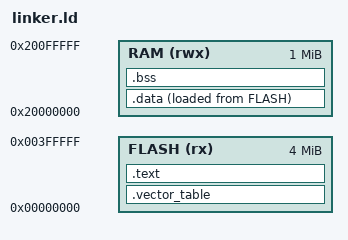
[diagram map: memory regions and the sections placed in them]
/*
 * Linker script for QEMU ARM (mps2-an385)
 * Memory map:
 *   FLASH: 0x00000000 - 0x003FFFFF (4 MB)
 *   RAM:   0x20000000 - 0x200FFFFF (1 MB)
 */

MEMORY
{
    FLASH (rx)  : ORIGIN = 0x00000000, LENGTH = 4M
    RAM   (rwx) : ORIGIN = 0x20000000, LENGTH = 1M
}

_estack = ORIGIN(RAM) + LENGTH(RAM);

SECTIONS
{
    .vector_table :
    {
        . = ALIGN(4);
        KEEP(*(.vector_table))
    } > FLASH

    .text :
    {
        *(.text*)
        *(.rodata*)
    } > FLASH

    .data :
    {
        _sdata = .;
        *(.data*)
        _edata = .;
    } > RAM AT > FLASH
    _sload = LOADADDR(.data);   /* FLASH load address for .data copy */

    .bss :
    {
        _sbss = .;
        *(.bss*)
        *(COMMON)
        _ebss = .;
    } > RAM
}
